# headsail register map
Vendor: tuni.fi; File version: 1.0
CPU: other r1p0, little endian, no MPU, no FPU, vendor SysTick, 2 interrupt priority bits
Registers are 32-bit, read-write, no defined reset value unless marked. A register's access mark holds for its fields unless they carry their own. Offsets are from the block's base; [hi:lo] are bit positions; lines under a group give offsets from that group; {n}, {i} and the like mark numbered series; 'fields as' and 'values as' point back to an identical list; <NAME> marks a mode.

## C2C_serial
Base 0x1FFC00000
0x00 Configuration group
  0x00 ID ro reset 0xABCD9876 — ID register. Constant ID value
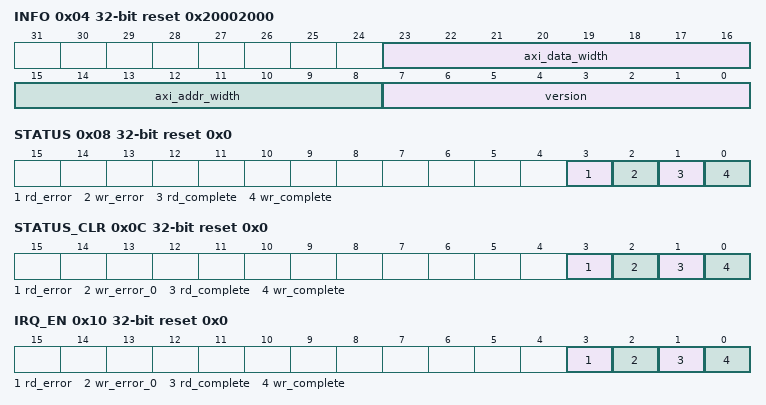
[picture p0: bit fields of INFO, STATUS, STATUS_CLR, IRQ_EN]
  0x04 INFO ro reset 0x20002000 (reset mask 0xFF00FF00) — Version number - AXI Address width - AXI Data width-Reserved
    [23:16] axi_data_width
    [15:8] axi_addr_width — AXI Address Width
    [7:0] version — Version number
  0x08 STATUS ro reset 0x0 — Holds status flags. Each Status Flag can either be cleared by writing to the STATUS_CLR register or when the STATUS register is read (must be configured)
    [3] rd_error — Status flag for read transfer error
    [2] wr_error — Status flag for write transfer error
    [1] rd_complete — Status flag for read transfer completion
    [0] wr_complete — Status flag for write transfer completion
  0x0C STATUS_CLR reset 0x0 — Acknowledging status register. Clearing each respective one by setting corresponding bit
    [3] rd_error — Acknowledging rd_error status bit. Clearing rd_error status flag by setting '1'
    [2] wr_error_0 — Acknowledging wr_error status bit. Clearing wr_error status flag by setting '1'
    [1] rd_complete — Acknowledging rd_complete status bit. Clearing rd_complete status flag by setting '1'
    [0] wr_complete — Acknowledging wr_complete status bit. Clearing wr_complete status flag by setting '1'
  0x10 IRQ_EN reset 0x0 — Configuring which of the interrupts are routed to the IRQ pin. Enabling each intterupt signal by setting corresponding bit. All of the interrupts can be enabled and disabled independent from each other.
    [3] rd_error — Configuring rd_error interrupt is routed to the IRQ pin by setting '1'
    [2] wr_error_0 — Configuring wr_error interrupt is routed to the IRQ pin by setting '1'
    [1] rd_complete — Configuring rd_complete interrupt is routed to the IRQ pin by setting '1'
    [0] wr_complete — Configuring wr_complete interrupt is routed to the IRQ pin by setting '1'
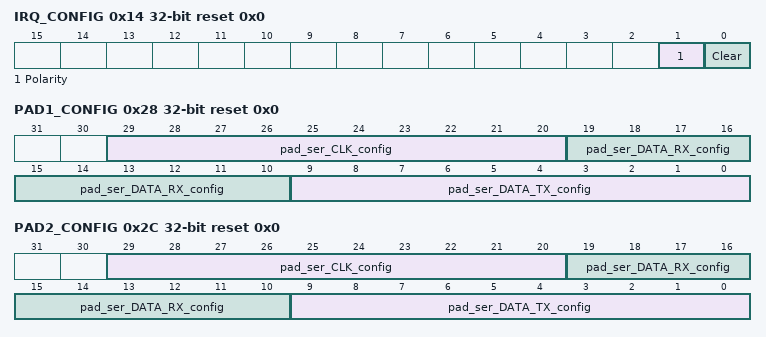
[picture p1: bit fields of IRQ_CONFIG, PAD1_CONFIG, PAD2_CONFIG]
  0x14 IRQ_CONFIG reset 0x0 — Configures the state (active high/low) and clearing conditions for the IRQ pin. Clear: '0' = Use STATUS_CLR to clear '1' = Auto Clear on Read of STATUS register Polarity: '0' = IRQ active low '1' = IRQ active high
    [1] Polarity — Polarity: '0' = IRQ active low '1' = IRQ active high
    [0] Clear — Clear: '0' = Use STATUS_CLR to clear '1' = Auto Clear on Read of STATUS register
  0x18 ADDRESS_MAPPING_TX reset 0x0 — Address Mapping for AXI4 slave interface. It provides a subset of the bits that will be used as a map value
  0x1C ADDRESS_MASKING_TX reset 0xFFFFFFFF — Address Masking for AXI4 slave interface. It specifies a bitmask. address_masking (i) = 1 : address_out(i) <=address_in(i) address_masking (i) = 0 : address_out(i) <= address_mapping(i) E.g. address_in = 0x70007000 address_masking= 0x0000FFFF address_mapping = 0xABCD0000 address_out = 0xABCD7000
  0x20 ADDRESS_MAPPING_RX reset 0x0 — Address Mapping for AXI4 master interface. It provides a subset of the bits that will be used as a map value
  0x24 ADDRESS_MASKING_RX reset 0xFFFFFFFF — Address Masking for AXI4 master interface. It specifies a bitmask. address_masking (i) = 1 : address_out(i) <=address_in(i) address_masking (i) = 0 : address_out(i) <= address_mapping(i) E.g. address_in = 0x70007000 address_masking= 0x0000FFFF address_mapping = 0xABCD0000 address_out = 0xABCD7000
  0x28 PAD1_CONFIG reset 0x0 (reset mask 0xFFC03FF0) — PAD configuration Register 1. It is used to perform proper configuration for the corresponding pads of the I/O ports 10 bits per PAD configuration 0: drive strenght / 1: drive strenght / 2: schmitt trigger / 3: schmitt trigger / 4: rate / 5: output en(0) / 6: hold / 7: pull enable / 8: pd(0)/pu(1) / 9: input en(1)
    [29:20] pad_ser_CLK_config — 0: drive strenght / 1: drive strenght / 2: schmitt trigger / 3: schmitt trigger / 4: rate / 5: output en(0) / 6: hold / 7: pull enable / 8: pd(0)/pu(1) / 9: input en(1)
    [19:10] pad_ser_DATA_RX_config — 0: drive strenght / 1: drive strenght / 2: schmitt trigger / 3: schmitt trigger / 4: rate / 5: output en(0) / 6: hold / 7: pull enable / 8: pd(0)/pu(1) / 9: input en(1)
    [9:0] pad_ser_DATA_TX_config — 0: drive strenght / 1: drive strenght / 2: schmitt trigger / 3: schmitt trigger / 4: rate / 5: output en(0) / 6: hold / 7: pull enable / 8: pd(0)/pu(1) / 9: input en(1)
  0x2C PAD2_CONFIG reset 0x0 (reset mask 0xFFC03FF0)
    fields as Configuration.PAD1_CONFIG
  0x40 CLK_DIVIDER_CONF
    [3:0] DIVIDER
  {0x44+4j} LANE_CONFIG[{j}] (j=0..3)
    [31:0] CONFIG
  {0x54+4j} TEST_DIAGNOSIS_CONFIG[{j}] (j=0..3)
    [31:0] CONFIG
  {0x64+4j} LANE_STATUS[{j}] (j=0..3) ro
    [31:0] STATUS
